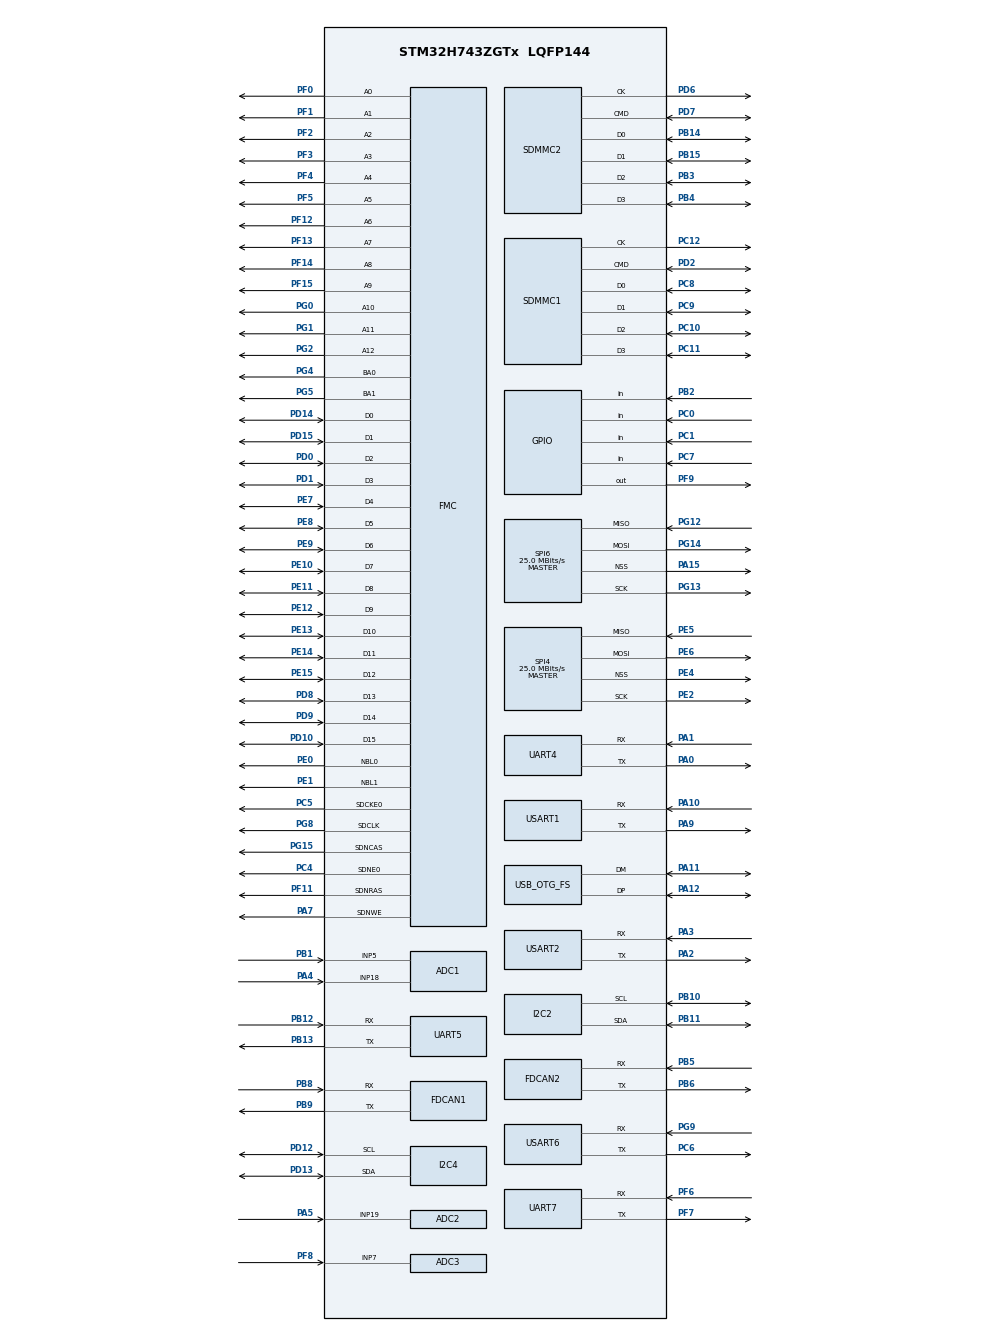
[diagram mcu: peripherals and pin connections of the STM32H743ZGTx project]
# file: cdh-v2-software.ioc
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ADC1.Channel-4\#ChannelRegularConversion=ADC_CHANNEL_18
ADC1.ClockPrescaler=ADC_CLOCK_ASYNC_DIV4
ADC1.NbrOfConversionFlag=1
ADC1.OffsetNumber-4\#ChannelRegularConversion=ADC_OFFSET_NONE
ADC1.OffsetSignedSaturation-4\#ChannelRegularConversion=DISABLE
ADC1.Rank-4\#ChannelRegularConversion=1
ADC1.SamplingTime-4\#ChannelRegularConversion=ADC_SAMPLETIME_1CYCLE_5
ADC1.master=1
ADC2.Channel-0\#ChannelRegularConversion=ADC_CHANNEL_19
ADC2.ClockPrescaler=ADC_CLOCK_ASYNC_DIV4
ADC2.NbrOfConversionFlag=1
ADC2.OffsetNumber-0\#ChannelRegularConversion=ADC_OFFSET_NONE
ADC2.OffsetSignedSaturation-0\#ChannelRegularConversion=DISABLE
ADC2.Rank-0\#ChannelRegularConversion=1
ADC2.SamplingTime-0\#ChannelRegularConversion=ADC_SAMPLETIME_1CYCLE_5
ADC3.Channel-0\#ChannelRegularConversion=ADC_CHANNEL_7
ADC3.ClockPrescaler=ADC_CLOCK_ASYNC_DIV4
ADC3.NbrOfConversionFlag=1
ADC3.OffsetNumber-0\#ChannelRegularConversion=ADC_OFFSET_NONE
ADC3.OffsetSignedSaturation-0\#ChannelRegularConversion=DISABLE
ADC3.Rank-0\#ChannelRegularConversion=1
ADC3.SamplingTime-0\#ChannelRegularConversion=ADC_SAMPLETIME_1CYCLE_5
CORTEX_M7.AccessPermission_S-Cortex_Memory_Protection_Unit_Region1_Settings_S=MPU_REGION_PRIV_RO
CORTEX_M7.AccessPermission_S-Cortex_Memory_Protection_Unit_Region2_Settings_S=MPU_REGION_FULL_ACCESS
CORTEX_M7.BaseAddress_S-Cortex_Memory_Protection_Unit_Region1_Settings_S=0x08000000
CORTEX_M7.BaseAddress_S-Cortex_Memory_Protection_Unit_Region2_Settings_S=0xC0000000
CORTEX_M7.DisableExec_S-Cortex_Memory_Protection_Unit_Region2_Settings_S=MPU_INSTRUCTION_ACCESS_DISABLE
CORTEX_M7.Enable_S-Cortex_Memory_Protection_Unit_Region1_Settings_S=MPU_REGION_ENABLE
CORTEX_M7.Enable_S-Cortex_Memory_Protection_Unit_Region2_Settings_S=MPU_REGION_ENABLE
CORTEX_M7.IsCacheable_S-Cortex_Memory_Protection_Unit_Region1_Settings_S=MPU_ACCESS_CACHEABLE
CORTEX_M7.Number_S-Cortex_Memory_Protection_Unit_Region2_Settings_S=MPU_REGION_NUMBER2
CORTEX_M7.Size_S-Cortex_Memory_Protection_Unit_Region1_Settings_S=MPU_REGION_SIZE_2MB
CORTEX_M7.Size_S-Cortex_Memory_Protection_Unit_Region2_Settings_S=MPU_REGION_SIZE_32MB
CORTEX_M7.SubRegionDisable_S-Cortex_Memory_Protection_Unit_Region1_Settings_S=0x88
CORTEX_M7.TypeExtField_S-Cortex_Memory_Protection_Unit_Region1_Settings_S=MPU_TEX_LEVEL1
CORTEX_M7.TypeExtField_S-Cortex_Memory_Protection_Unit_Region2_Settings_S=MPU_TEX_LEVEL1
CORTEX_M7.default_mode_Activation=1
FATFS.BSP.number=1
FATFS0.BSP.STBoard=false
FATFS0.BSP.api=Unknown
FATFS0.BSP.instance=PC7
FATFS0.BSP.ip=GPIO
FATFS0.BSP.mode=Input
FATFS0.BSP.name=Detect_SDIO
FATFS0.BSP.solution=PC7
FDCAN1.CalculateBaudRateNominal=499999
FDCAN1.CalculateTimeBitNominal=2000
FDCAN1.CalculateTimeQuantumNominal=16.666666666666668
FDCAN1.FrameFormat=FDCAN_FRAME_FD_BRS
FDCAN1.NominalPrescaler=2
FDCAN1.NominalTimeSeg1=95
FDCAN1.NominalTimeSeg2=24
FDCAN2.CalculateBaudRateNominal=499999
FDCAN2.CalculateTimeBitNominal=2000
FDCAN2.CalculateTimeQuantumNominal=16.666666666666668
FDCAN2.FrameFormat=FDCAN_FRAME_FD_BRS
FDCAN2.NominalPrescaler=2
FDCAN2.NominalTimeSeg1=95
FDCAN2.NominalTimeSeg2=24
FMC.CASLatency1=FMC_SDRAM_CAS_LATENCY_2
FMC.ColumnBitsNumber1=FMC_SDRAM_COLUMN_BITS_NUM_9
FMC.ExitSelfRefreshDelay1=10
FMC.LoadToActiveDelay1=2
FMC.RCDDelay1=3
FMC.RPDelay1=3
FMC.ReadBurst1=FMC_SDRAM_RBURST_ENABLE
FMC.ReadPipeDelay1=FMC_SDRAM_RPIPE_DELAY_2
FMC.ReadPipeDelay2=FMC_SDRAM_RPIPE_DELAY_2
FMC.RowCycleDelay1=9
FMC.RowCycleDelay2=9
FMC.SDClockPeriod1=FMC_SDRAM_CLOCK_PERIOD_3
FMC.SDClockPeriod2=FMC_SDRAM_CLOCK_PERIOD_3
FMC.SelfRefreshTime1=6
FMC.WriteRecoveryTime1=3
FREERTOS.HEAP_NUMBER=4
FREERTOS.Tasks01=defaultTask,24,128,StartDefaultTask,Default,NULL,Dynamic,NULL,NULL
FREERTOS.configTOTAL_HEAP_SIZE=262144
FREERTOS.configUSE_NEWLIB_REENTRANT=0
I2C2.Timing=0x00909BEB
I2C4.CustomTiming=Disabled
I2C4.Timing=0x00909BEB
Mcu.Family=STM32H7
Mcu.Name=STM32H743ZGTx
Mcu.Package=LQFP144
NVIC.OTG_FS_IRQn=true\:5\:0\:false\:false\:true\:true\:false\:true\:true
NVIC.PriorityGroup=NVIC_PRIORITYGROUP_4
NVIC.TIM1_UP_IRQn=true\:15\:0\:false\:false\:true\:false\:false\:true\:true
NVIC.TimeBase=TIM1_UP_IRQn
NVIC.TimeBaseIP=TIM1
PA0.Mode=Asynchronous
PA0.Signal=UART4_TX
PA1.Mode=Asynchronous
PA1.Signal=UART4_RX
PA10.Mode=Asynchronous
PA10.Signal=USART1_RX
PA11.Mode=Device_Only
PA11.Signal=USB_OTG_FS_DM
PA12.Mode=Device_Only
PA12.Signal=USB_OTG_FS_DP
PA13\ (JTMS/SWDIO).Mode=Serial_Wire
PA13\ (JTMS/SWDIO).Signal=DEBUG_JTMS-SWDIO
PA14\ (JTCK/SWCLK).Mode=Serial_Wire
PA14\ (JTCK/SWCLK).Signal=DEBUG_JTCK-SWCLK
PA15\ (JTDI).Mode=NSS_Signal_Hard_Output
PA15\ (JTDI).Signal=SPI6_NSS
PA2.Mode=Asynchronous
PA2.Signal=USART2_TX
PA3.Mode=Asynchronous
PA3.Signal=USART2_RX
PA4.Signal=ADCx_INP18
PA5.Signal=ADCx_INP19
PA7.Signal=FMC_SDNWE
PA9.Mode=Asynchronous
PA9.Signal=USART1_TX
PB1.Signal=ADCx_INP5
PB10.Mode=I2C
PB10.Signal=I2C2_SCL
PB11.Mode=I2C
PB11.Signal=I2C2_SDA
PB12.Mode=Asynchronous
PB12.Signal=UART5_RX
PB13.Mode=Asynchronous
PB13.Signal=UART5_TX
PB14.Mode=SD_4_bits_Wide_bus
PB14.Signal=SDMMC2_D0
PB15.Mode=SD_4_bits_Wide_bus
PB15.Signal=SDMMC2_D1
PB2.GPIO_PuPd=GPIO_PULLUP
PB2.Signal=GPIO_Input
PB3\ (JTDO/TRACESWO).Mode=SD_4_bits_Wide_bus
PB3\ (JTDO/TRACESWO).Signal=SDMMC2_D2
PB4\ (NJTRST).Mode=SD_4_bits_Wide_bus
PB4\ (NJTRST).Signal=SDMMC2_D3
PB5.Mode=FDCAN_Activate
PB5.Signal=FDCAN2_RX
PB6.Mode=FDCAN_Activate
PB6.Signal=FDCAN2_TX
PB8.Mode=FDCAN_Activate
PB8.Signal=FDCAN1_RX
PB9.Mode=FDCAN_Activate
PB9.Signal=FDCAN1_TX
PC0.Signal=GPIO_Input
PC1.Signal=GPIO_Input
PC10.Mode=SD_4_bits_Wide_bus
PC10.Signal=SDMMC1_D2
PC11.Mode=SD_4_bits_Wide_bus
PC11.Signal=SDMMC1_D3
PC12.Mode=SD_4_bits_Wide_bus
PC12.Signal=SDMMC1_CK
PC14-OSC32_IN\ (OSC32_IN).Mode=LSE-External-Oscillator
PC14-OSC32_IN\ (OSC32_IN).Signal=RCC_OSC32_IN
PC15-OSC32_OUT\ (OSC32_OUT).Mode=LSE-External-Oscillator
PC15-OSC32_OUT\ (OSC32_OUT).Signal=RCC_OSC32_OUT
PC4.Mode=SdramChipSelect1_1
PC4.Signal=FMC_SDNE0
PC5.Mode=SdramChipSelect1_1
PC5.Signal=FMC_SDCKE0
PC6.Mode=Asynchronous
PC6.Signal=USART6_TX
PC7.GPIO_PuPd=GPIO_PULLUP
PC7.Signal=GPIO_Input
PC8.Mode=SD_4_bits_Wide_bus
PC8.Signal=SDMMC1_D0
PC9.Mode=SD_4_bits_Wide_bus
PC9.Signal=SDMMC1_D1
PD0.Signal=FMC_D2_DA2
PD1.Signal=FMC_D3_DA3
PD10.Signal=FMC_D15_DA15
PD12.Mode=I2C
PD12.Signal=I2C4_SCL
PD13.Mode=I2C
PD13.Signal=I2C4_SDA
PD14.Signal=FMC_D0_DA0
PD15.Signal=FMC_D1_DA1
PD2.Mode=SD_4_bits_Wide_bus
PD2.Signal=SDMMC1_CMD
PD6.Mode=SD_4_bits_Wide_bus
PD6.Signal=SDMMC2_CK
PD7.Mode=SD_4_bits_Wide_bus
PD7.Signal=SDMMC2_CMD
PD8.Signal=FMC_D13_DA13
PD9.Signal=FMC_D14_DA14
PE0.Signal=FMC_NBL0
PE1.Signal=FMC_NBL1
PE10.Signal=FMC_D7_DA7
PE11.Signal=FMC_D8_DA8
PE12.Signal=FMC_D9_DA9
PE13.Signal=FMC_D10_DA10
PE14.Signal=FMC_D11_DA11
PE15.Signal=FMC_D12_DA12
PE2.Mode=Full_Duplex_Master
PE2.Signal=SPI4_SCK
PE4.Mode=NSS_Signal_Hard_Output
PE4.Signal=SPI4_NSS
PE5.Mode=Full_Duplex_Master
PE5.Signal=SPI4_MISO
PE6.Mode=Full_Duplex_Master
PE6.Signal=SPI4_MOSI
PE7.Signal=FMC_D4_DA4
PE8.Signal=FMC_D5_DA5
PE9.Signal=FMC_D6_DA6
PF0.Signal=FMC_A0
PF1.Signal=FMC_A1
PF11.Signal=FMC_SDNRAS
PF12.Signal=FMC_A6
PF13.Signal=FMC_A7
PF14.Signal=FMC_A8
PF15.Signal=FMC_A9
PF2.Signal=FMC_A2
PF3.Signal=FMC_A3
PF4.Signal=FMC_A4
PF5.Signal=FMC_A5
PF6.Mode=Asynchronous
PF6.Signal=UART7_RX
PF7.Mode=Asynchronous
PF7.Signal=UART7_TX
PF8.Mode=IN7-Single-Ended
PF8.Signal=ADC3_INP7
PF9.Signal=GPIO_Output
PG0.Signal=FMC_A10
PG1.Signal=FMC_A11
PG12.Mode=Full_Duplex_Master
PG12.Signal=SPI6_MISO
PG13.Mode=Full_Duplex_Master
PG13.Signal=SPI6_SCK
PG14.Mode=Full_Duplex_Master
PG14.Signal=SPI6_MOSI
PG15.Signal=FMC_SDNCAS
PG2.Signal=FMC_A12
PG4.Signal=FMC_A14_BA0
PG5.Signal=FMC_A15_BA1
PG8.Signal=FMC_SDCLK
PG9.Mode=Asynchronous
PG9.Signal=USART6_RX
PH0-OSC_IN\ (PH0).Mode=HSE-External-Oscillator
PH0-OSC_IN\ (PH0).Signal=RCC_OSC_IN
PH1-OSC_OUT\ (PH1).Mode=HSE-External-Oscillator
PH1-OSC_OUT\ (PH1).Signal=RCC_OSC_OUT
ProjectManager.HeapSize=0x200
ProjectManager.StackSize=0x400
ProjectManager.TargetToolchain=CMake
RAMECC.Instance-RAMECC1_Monitor1=RAMECC1_Monitor1
RAMECC.Instance-RAMECC1_Monitor2=RAMECC1_Monitor2
RAMECC.Instance-RAMECC1_Monitor3=RAMECC1_Monitor3
RAMECC.Instance-RAMECC1_Monitor4=RAMECC1_Monitor4
RAMECC.Instance-RAMECC1_Monitor5=RAMECC1_Monitor5
RAMECC.Instance-RAMECC2_Monitor1=RAMECC2_Monitor1
RAMECC.Instance-RAMECC2_Monitor2=RAMECC2_Monitor2
RAMECC.Instance-RAMECC2_Monitor3=RAMECC2_Monitor3
RAMECC.Instance-RAMECC2_Monitor4=RAMECC2_Monitor4
RAMECC.Instance-RAMECC2_Monitor5=RAMECC2_Monitor5
RAMECC.Instance-RAMECC3_Monitor1=RAMECC3_Monitor1
RAMECC.Instance-RAMECC3_Monitor2=RAMECC3_Monitor2
RCC.ADCFreq_Value=75000000
RCC.APB1Freq_Value=120000000
RCC.APB2Freq_Value=120000000
RCC.APB3Freq_Value=120000000
RCC.APB4Freq_Value=120000000
RCC.CortexFreq_Value=240000000
RCC.D1PPRE=RCC_APB3_DIV2
RCC.D2PPRE1=RCC_APB1_DIV2
RCC.D2PPRE2=RCC_APB2_DIV2
RCC.D3PPRE=RCC_APB4_DIV2
RCC.DIVM1=1
RCC.DIVM2=1
RCC.DIVM3=1
RCC.DIVN1=60
RCC.DIVN2=18
RCC.DIVN3=30
RCC.DIVQ1=4
RCC.DIVQ2=3
RCC.DIVQ3=5
RCC.DIVR2=3
RCC.DIVR3=6
RCC.EnbaleCSS=false
RCC.HCLKFreq_Value=240000000
RCC.HSE_VALUE=8000000
RCC.I2C123CLockSelection=RCC_I2C123CLKSOURCE_PLL3
RCC.I2C4CLockSelection=RCC_I2C4CLKSOURCE_PLL3
RCC.PLL2FRACN=6144
RCC.PLL3FRACN=0
RCC.PLLFRACN=0
RCC.PLLSourceVirtual=RCC_PLLSOURCE_HSE
RCC.SDMMC1CLockSelection=RCC_SDMMCCLKSOURCE_PLL2
RCC.SPI6CLockSelection=RCC_SPI6CLKSOURCE_PLL2
RCC.SYSCLKFreq_VALUE=240000000
RCC.SYSCLKSource=RCC_SYSCLKSOURCE_PLLCLK
RCC.Spi45ClockSelection=RCC_SPI45CLKSOURCE_PLL2
RCC.USART16CLockSelection=RCC_USART16CLKSOURCE_PLL2
RCC.USART234578CLockSelection=RCC_USART234578CLKSOURCE_PLL2
RCC.USBCLockSelection=RCC_USBCLKSOURCE_PLL3
RCC.USBFreq_Value=48000000
SH.ADCx_INP18.0=ADC2_INP18
SH.ADCx_INP18.1=ADC1_INP18,IN18-Single-Ended
SH.ADCx_INP19.0=ADC2_INP19,IN19-Single-Ended
SH.ADCx_INP5.0=ADC1_INP5,IN5-Single-Ended
SH.FMC_A0.0=FMC_A0,13b-sda1
SH.FMC_A1.0=FMC_A1,13b-sda1
SH.FMC_A10.0=FMC_A10,13b-sda1
SH.FMC_A11.0=FMC_A11,13b-sda1
SH.FMC_A12.0=FMC_A12,13b-sda1
SH.FMC_A14_BA0.0=FMC_BA0,FourSdramBanks1
SH.FMC_A15_BA1.0=FMC_BA1,FourSdramBanks1
SH.FMC_A2.0=FMC_A2,13b-sda1
SH.FMC_A3.0=FMC_A3,13b-sda1
SH.FMC_A4.0=FMC_A4,13b-sda1
SH.FMC_A5.0=FMC_A5,13b-sda1
SH.FMC_A6.0=FMC_A6,13b-sda1
SH.FMC_A7.0=FMC_A7,13b-sda1
SH.FMC_A8.0=FMC_A8,13b-sda1
SH.FMC_A9.0=FMC_A9,13b-sda1
SH.FMC_D0_DA0.0=FMC_D0,sd-16b-d1
SH.FMC_D10_DA10.0=FMC_D10,sd-16b-d1
SH.FMC_D11_DA11.0=FMC_D11,sd-16b-d1
SH.FMC_D12_DA12.0=FMC_D12,sd-16b-d1
SH.FMC_D13_DA13.0=FMC_D13,sd-16b-d1
SH.FMC_D14_DA14.0=FMC_D14,sd-16b-d1
SH.FMC_D15_DA15.0=FMC_D15,sd-16b-d1
SH.FMC_D1_DA1.0=FMC_D1,sd-16b-d1
SH.FMC_D2_DA2.0=FMC_D2,sd-16b-d1
SH.FMC_D3_DA3.0=FMC_D3,sd-16b-d1
SH.FMC_D4_DA4.0=FMC_D4,sd-16b-d1
SH.FMC_D5_DA5.0=FMC_D5,sd-16b-d1
SH.FMC_D6_DA6.0=FMC_D6,sd-16b-d1
SH.FMC_D7_DA7.0=FMC_D7,sd-16b-d1
SH.FMC_D8_DA8.0=FMC_D8,sd-16b-d1
SH.FMC_D9_DA9.0=FMC_D9,sd-16b-d1
SH.FMC_NBL0.0=FMC_NBL0,Sd2ByteEnable1
SH.FMC_NBL1.0=FMC_NBL1,Sd2ByteEnable1
SH.FMC_SDCLK.0=FMC_SDCLK,13b-sda1
SH.FMC_SDNCAS.0=FMC_SDNCAS,13b-sda1
SH.FMC_SDNRAS.0=FMC_SDNRAS,13b-sda1
SH.FMC_SDNWE.0=FMC_SDNWE,13b-sda1
SPI4.CalculateBaudRate=25.0 MBits/s
SPI4.Direction=SPI_DIRECTION_2LINES
SPI4.Mode=SPI_MODE_MASTER
SPI4.VirtualNSS=VM_NSSHARD
SPI4.VirtualType=VM_MASTER
SPI6.CalculateBaudRate=25.0 MBits/s
SPI6.Direction=SPI_DIRECTION_2LINES
SPI6.Mode=SPI_MODE_MASTER
SPI6.VirtualNSS=VM_NSSHARD
SPI6.VirtualType=VM_MASTER
USART1.VirtualMode-Asynchronous=VM_ASYNC
USART2.VirtualMode-Asynchronous=VM_ASYNC
USART6.VirtualMode-Asynchronous=VM_ASYNC
USB_DEVICE.CLASS_NAME_FS=CDC
USB_DEVICE.VirtualMode-CDC_FS=Cdc
USB_DEVICE.VirtualModeFS=Cdc_FS
USB_OTG_FS.VirtualMode=Device_Only
VP_CRC_VS_CRC.Mode=CRC_Activate
VP_FATFS_VS_SDIO.Mode=SDIO
VP_FREERTOS_VS_CMSIS_V2.Mode=CMSIS_V2
VP_IWDG1_VS_IWDG.Mode=IWDG_Activate
VP_MEMORYMAP_VS_MEMORYMAP.Mode=CurAppReg
VP_RAMECC_VS_D1_1.Mode=RAMECC1_Monitor1
VP_RAMECC_VS_D1_2.Mode=RAMECC1_Monitor2
VP_RAMECC_VS_D1_3.Mode=RAMECC1_Monitor3
VP_RAMECC_VS_D1_4.Mode=RAMECC1_Monitor4
VP_RAMECC_VS_D1_5.Mode=RAMECC1_Monitor5
VP_RAMECC_VS_D2_1.Mode=RAMECC2_Monitor1
VP_RAMECC_VS_D2_2.Mode=RAMECC2_Monitor2
VP_RAMECC_VS_D2_3.Mode=RAMECC2_Monitor3
VP_RAMECC_VS_D2_4.Mode=RAMECC2_Monitor4
VP_RAMECC_VS_D2_5.Mode=RAMECC2_Monitor5
VP_RAMECC_VS_D3_1.Mode=RAMECC3_Monitor1
VP_RAMECC_VS_D3_2.Mode=RAMECC3_Monitor2
VP_SYS_VS_tim1.Mode=TIM1
VP_TIM6_VS_ClockSourceINT.Mode=Enable_Timer
VP_TIM7_VS_ClockSourceINT.Mode=Enable_Timer
VP_USB_DEVICE_VS_USB_DEVICE_CDC_FS.Mode=CDC_FS
board=custom

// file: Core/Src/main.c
/* USER CODE BEGIN Header */
/**
  ******************************************************************************
  * @file           : main.c
  * @brief          : Main program body
  ******************************************************************************
  * @attention
  *
  * Copyright (c) 2026 STMicroelectronics.
  * All rights reserved.
  *
  * This software is licensed under terms that can be found in the LICENSE file
  * in the root directory of this software component.
  * If no LICENSE file comes with this software, it is provided AS-IS.
  *
  ******************************************************************************
  */
/* USER CODE END Header */
#include "main.h"
#include "FreeRTOS.h"
#include "cmsis_os2.h"
#include "fatfs.h"
#include "usb_device.h"

/* USER CODE BEGIN Includes */
#include "cdh_main.h"

/* USER CODE END Includes */

ADC_HandleTypeDef hadc1;
ADC_HandleTypeDef hadc2;
ADC_HandleTypeDef hadc3;

CRC_HandleTypeDef hcrc;

FDCAN_HandleTypeDef hfdcan1;
FDCAN_HandleTypeDef hfdcan2;

I2C_HandleTypeDef hi2c2;
I2C_HandleTypeDef hi2c4;

IWDG_HandleTypeDef hiwdg1;

RAMECC_HandleTypeDef hramecc1_m1;
RAMECC_HandleTypeDef hramecc1_m2;
RAMECC_HandleTypeDef hramecc1_m3;
RAMECC_HandleTypeDef hramecc1_m4;
RAMECC_HandleTypeDef hramecc1_m5;
RAMECC_HandleTypeDef hramecc2_m1;
RAMECC_HandleTypeDef hramecc2_m2;
RAMECC_HandleTypeDef hramecc2_m3;
RAMECC_HandleTypeDef hramecc2_m4;
RAMECC_HandleTypeDef hramecc2_m5;
RAMECC_HandleTypeDef hramecc3_m1;
RAMECC_HandleTypeDef hramecc3_m2;

SD_HandleTypeDef hsd1;
SD_HandleTypeDef hsd2;

SPI_HandleTypeDef hspi4;
SPI_HandleTypeDef hspi6;

TIM_HandleTypeDef htim6;
TIM_HandleTypeDef htim7;

UART_HandleTypeDef huart4;
UART_HandleTypeDef huart5;
UART_HandleTypeDef huart7;
UART_HandleTypeDef huart1;
UART_HandleTypeDef huart2;
UART_HandleTypeDef huart6;

SDRAM_HandleTypeDef hsdram1;

/* Definitions for defaultTask */
osThreadId_t defaultTaskHandle;
const osThreadAttr_t defaultTask_attributes = {
  .name = "defaultTask",
  .stack_size = 128 * 4,
  .priority = (osPriority_t) osPriorityNormal,
};

void SystemClock_Config(void);
void PeriphCommonClock_Config(void);
static void MPU_Config(void);
static void MX_GPIO_Init(void);
static void MX_ADC1_Init(void);
static void MX_ADC2_Init(void);
static void MX_ADC3_Init(void);
static void MX_FDCAN1_Init(void);
static void MX_FDCAN2_Init(void);
static void MX_FMC_Init(void);
static void MX_I2C2_Init(void);
static void MX_I2C4_Init(void);
static void MX_SDMMC1_SD_Init(void);
static void MX_SDMMC2_SD_Init(void);
static void MX_SPI4_Init(void);
static void MX_SPI6_Init(void);
static void MX_UART4_Init(void);
static void MX_UART5_Init(void);
static void MX_UART7_Init(void);
static void MX_USART1_UART_Init(void);
static void MX_USART2_UART_Init(void);
static void MX_USART6_UART_Init(void);
static void MX_CRC_Init(void);
static void MX_IWDG1_Init(void);
static void MX_RAMECC_Init(void);
static void MX_TIM6_Init(void);
static void MX_TIM7_Init(void);
void StartDefaultTask(void *argument);

int main(void)
{

  /* MPU Configuration--------------------------------------------------------*/
  MPU_Config();

  /* MCU Configuration--------------------------------------------------------*/

  /* Configure The Vector Table address */
  SCB->VTOR = 0x08000000;

  /* Reset of all peripherals, Initializes the Flash interface and the Systick. */
  HAL_Init();

  /* Configure the system clock */
  SystemClock_Config();

  /* Configure the peripherals common clocks */
  PeriphCommonClock_Config();

  /* Initialize all configured peripherals */
  MX_GPIO_Init();
  MX_ADC1_Init();
  MX_ADC2_Init();
  MX_ADC3_Init();
  MX_FDCAN1_Init();
  MX_FDCAN2_Init();
  MX_FMC_Init();
  MX_I2C2_Init();
  MX_I2C4_Init();
  MX_SDMMC1_SD_Init();
  MX_SDMMC2_SD_Init();
  MX_SPI4_Init();
  MX_SPI6_Init();
  MX_UART4_Init();
  MX_UART5_Init();
  MX_UART7_Init();
  MX_USART1_UART_Init();
  MX_USART2_UART_Init();
  MX_USART6_UART_Init();
  MX_CRC_Init();
  MX_IWDG1_Init();
  MX_RAMECC_Init();
  MX_TIM6_Init();
  MX_TIM7_Init();
  MX_FATFS_Init();

  /* Init scheduler */
  osKernelInitialize();

  /* Create the thread(s) */
  /* creation of defaultTask */
  defaultTaskHandle = osThreadNew(StartDefaultTask, NULL, &defaultTask_attributes);

  /* Start scheduler */
  osKernelStart();

  /* We should never get here as control is now taken by the scheduler */

  /* Infinite loop */
  while (1)
  {

  }
}

void SystemClock_Config(void)
{
  RCC_OscInitTypeDef RCC_OscInitStruct = {0};
  RCC_ClkInitTypeDef RCC_ClkInitStruct = {0};

  /** Supply configuration update enable
  */
  HAL_PWREx_ConfigSupply(PWR_LDO_SUPPLY);

  /** Configure the main internal regulator output voltage
  */
  __HAL_PWR_VOLTAGESCALING_CONFIG(PWR_REGULATOR_VOLTAGE_SCALE0);

  while(!__HAL_PWR_GET_FLAG(PWR_FLAG_VOSRDY)) {}

  /** Initializes the RCC Oscillators according to the specified parameters
  * in the RCC_OscInitTypeDef structure.
  */
  RCC_OscInitStruct.OscillatorType = RCC_OSCILLATORTYPE_LSI|RCC_OSCILLATORTYPE_HSE;
  RCC_OscInitStruct.HSEState = RCC_HSE_ON;
  RCC_OscInitStruct.LSIState = RCC_LSI_ON;
  RCC_OscInitStruct.PLL.PLLState = RCC_PLL_ON;
  RCC_OscInitStruct.PLL.PLLSource = RCC_PLLSOURCE_HSE;
  RCC_OscInitStruct.PLL.PLLM = 1;
  RCC_OscInitStruct.PLL.PLLN = 60;
  RCC_OscInitStruct.PLL.PLLP = 2;
  RCC_OscInitStruct.PLL.PLLQ = 4;
  RCC_OscInitStruct.PLL.PLLR = 2;
  RCC_OscInitStruct.PLL.PLLRGE = RCC_PLL1VCIRANGE_3;
  RCC_OscInitStruct.PLL.PLLVCOSEL = RCC_PLL1VCOWIDE;
  RCC_OscInitStruct.PLL.PLLFRACN = 0;
  if (HAL_RCC_OscConfig(&RCC_OscInitStruct) != HAL_OK)
  {
    Error_Handler();
  }

  /** Initializes the CPU, AHB and APB buses clocks
  */
  RCC_ClkInitStruct.ClockType = RCC_CLOCKTYPE_HCLK|RCC_CLOCKTYPE_SYSCLK
                              |RCC_CLOCKTYPE_PCLK1|RCC_CLOCKTYPE_PCLK2
                              |RCC_CLOCKTYPE_D3PCLK1|RCC_CLOCKTYPE_D1PCLK1;
  RCC_ClkInitStruct.SYSCLKSource = RCC_SYSCLKSOURCE_PLLCLK;
  RCC_ClkInitStruct.SYSCLKDivider = RCC_SYSCLK_DIV1;
  RCC_ClkInitStruct.AHBCLKDivider = RCC_HCLK_DIV1;
  RCC_ClkInitStruct.APB3CLKDivider = RCC_APB3_DIV2;
  RCC_ClkInitStruct.APB1CLKDivider = RCC_APB1_DIV2;
  RCC_ClkInitStruct.APB2CLKDivider = RCC_APB2_DIV2;
  RCC_ClkInitStruct.APB4CLKDivider = RCC_APB4_DIV2;

  if (HAL_RCC_ClockConfig(&RCC_ClkInitStruct, FLASH_LATENCY_4) != HAL_OK)
  {
    Error_Handler();
  }
}

void PeriphCommonClock_Config(void)
{
  RCC_PeriphCLKInitTypeDef PeriphClkInitStruct = {0};

  /** Initializes the peripherals clock
  */
  PeriphClkInitStruct.PeriphClockSelection = RCC_PERIPHCLK_USB|RCC_PERIPHCLK_I2C4
                              |RCC_PERIPHCLK_SPI6|RCC_PERIPHCLK_ADC
                              |RCC_PERIPHCLK_I2C2|RCC_PERIPHCLK_SDMMC
                              |RCC_PERIPHCLK_SPI4|RCC_PERIPHCLK_UART5
                              |RCC_PERIPHCLK_USART1|RCC_PERIPHCLK_USART6
                              |RCC_PERIPHCLK_UART7|RCC_PERIPHCLK_UART4
                              |RCC_PERIPHCLK_USART2;
  PeriphClkInitStruct.PLL2.PLL2M = 1;
  PeriphClkInitStruct.PLL2.PLL2N = 18;
  PeriphClkInitStruct.PLL2.PLL2P = 2;
  PeriphClkInitStruct.PLL2.PLL2Q = 3;
  PeriphClkInitStruct.PLL2.PLL2R = 3;
  PeriphClkInitStruct.PLL2.PLL2RGE = RCC_PLL2VCIRANGE_3;
  PeriphClkInitStruct.PLL2.PLL2VCOSEL = RCC_PLL2VCOMEDIUM;
  PeriphClkInitStruct.PLL2.PLL2FRACN = 6144;
  PeriphClkInitStruct.PLL3.PLL3M = 1;
  PeriphClkInitStruct.PLL3.PLL3N = 30;
  PeriphClkInitStruct.PLL3.PLL3P = 2;
  PeriphClkInitStruct.PLL3.PLL3Q = 5;
  PeriphClkInitStruct.PLL3.PLL3R = 6;
  PeriphClkInitStruct.PLL3.PLL3RGE = RCC_PLL3VCIRANGE_3;
  PeriphClkInitStruct.PLL3.PLL3VCOSEL = RCC_PLL3VCOWIDE;
  PeriphClkInitStruct.PLL3.PLL3FRACN = 0;
  PeriphClkInitStruct.SdmmcClockSelection = RCC_SDMMCCLKSOURCE_PLL2;
  PeriphClkInitStruct.Spi45ClockSelection = RCC_SPI45CLKSOURCE_PLL2;
  PeriphClkInitStruct.Usart234578ClockSelection = RCC_USART234578CLKSOURCE_PLL2;
  PeriphClkInitStruct.Usart16ClockSelection = RCC_USART16CLKSOURCE_PLL2;
  PeriphClkInitStruct.I2c123ClockSelection = RCC_I2C123CLKSOURCE_PLL3;
  PeriphClkInitStruct.UsbClockSelection = RCC_USBCLKSOURCE_PLL3;
  PeriphClkInitStruct.I2c4ClockSelection = RCC_I2C4CLKSOURCE_PLL3;
  PeriphClkInitStruct.AdcClockSelection = RCC_ADCCLKSOURCE_PLL2;
  PeriphClkInitStruct.Spi6ClockSelection = RCC_SPI6CLKSOURCE_PLL2;
  if (HAL_RCCEx_PeriphCLKConfig(&PeriphClkInitStruct) != HAL_OK)
  {
    Error_Handler();
  }
}

static void MX_ADC1_Init(void)
{

  ADC_MultiModeTypeDef multimode = {0};
  ADC_ChannelConfTypeDef sConfig = {0};

  /** Common config
  */
  hadc1.Instance = ADC1;
  hadc1.Init.ClockPrescaler = ADC_CLOCK_ASYNC_DIV4;
  hadc1.Init.Resolution = ADC_RESOLUTION_16B;
  hadc1.Init.ScanConvMode = ADC_SCAN_DISABLE;
  hadc1.Init.EOCSelection = ADC_EOC_SINGLE_CONV;
  hadc1.Init.LowPowerAutoWait = DISABLE;
  hadc1.Init.ContinuousConvMode = DISABLE;
  hadc1.Init.NbrOfConversion = 1;
  hadc1.Init.DiscontinuousConvMode = DISABLE;
  hadc1.Init.ExternalTrigConv = ADC_SOFTWARE_START;
  hadc1.Init.ExternalTrigConvEdge = ADC_EXTERNALTRIGCONVEDGE_NONE;
  hadc1.Init.ConversionDataManagement = ADC_CONVERSIONDATA_DR;
  hadc1.Init.Overrun = ADC_OVR_DATA_PRESERVED;
  hadc1.Init.LeftBitShift = ADC_LEFTBITSHIFT_NONE;
  hadc1.Init.OversamplingMode = DISABLE;
  hadc1.Init.Oversampling.Ratio = 1;
  if (HAL_ADC_Init(&hadc1) != HAL_OK)
  {
    Error_Handler();
  }

  /** Configure the ADC multi-mode
  */
  multimode.Mode = ADC_MODE_INDEPENDENT;
  if (HAL_ADCEx_MultiModeConfigChannel(&hadc1, &multimode) != HAL_OK)
  {
    Error_Handler();
  }

  /** Configure Regular Channel
  */
  sConfig.Channel = ADC_CHANNEL_18;
  sConfig.Rank = ADC_REGULAR_RANK_1;
  sConfig.SamplingTime = ADC_SAMPLETIME_1CYCLE_5;
  sConfig.SingleDiff = ADC_SINGLE_ENDED;
  sConfig.OffsetNumber = ADC_OFFSET_NONE;
  sConfig.Offset = 0;
  sConfig.OffsetSignedSaturation = DISABLE;
  if (HAL_ADC_ConfigChannel(&hadc1, &sConfig) != HAL_OK)
  {
    Error_Handler();
  }

}

static void MX_ADC2_Init(void)
{

  ADC_ChannelConfTypeDef sConfig = {0};

  /** Common config
  */
  hadc2.Instance = ADC2;
  hadc2.Init.ClockPrescaler = ADC_CLOCK_ASYNC_DIV4;
  hadc2.Init.Resolution = ADC_RESOLUTION_16B;
  hadc2.Init.ScanConvMode = ADC_SCAN_DISABLE;
  hadc2.Init.EOCSelection = ADC_EOC_SINGLE_CONV;
  hadc2.Init.LowPowerAutoWait = DISABLE;
  hadc2.Init.ContinuousConvMode = DISABLE;
  hadc2.Init.NbrOfConversion = 1;
  hadc2.Init.DiscontinuousConvMode = DISABLE;
  hadc2.Init.ExternalTrigConv = ADC_SOFTWARE_START;
  hadc2.Init.ExternalTrigConvEdge = ADC_EXTERNALTRIGCONVEDGE_NONE;
  hadc2.Init.ConversionDataManagement = ADC_CONVERSIONDATA_DR;
  hadc2.Init.Overrun = ADC_OVR_DATA_PRESERVED;
  hadc2.Init.LeftBitShift = ADC_LEFTBITSHIFT_NONE;
  hadc2.Init.OversamplingMode = DISABLE;
  hadc2.Init.Oversampling.Ratio = 1;
  if (HAL_ADC_Init(&hadc2) != HAL_OK)
  {
    Error_Handler();
  }

  /** Configure Regular Channel
  */
  sConfig.Channel = ADC_CHANNEL_19;
  sConfig.Rank = ADC_REGULAR_RANK_1;
  sConfig.SamplingTime = ADC_SAMPLETIME_1CYCLE_5;
  sConfig.SingleDiff = ADC_SINGLE_ENDED;
  sConfig.OffsetNumber = ADC_OFFSET_NONE;
  sConfig.Offset = 0;
  sConfig.OffsetSignedSaturation = DISABLE;
  if (HAL_ADC_ConfigChannel(&hadc2, &sConfig) != HAL_OK)
  {
    Error_Handler();
  }

}

static void MX_ADC3_Init(void)
{

  ADC_ChannelConfTypeDef sConfig = {0};

  /** Common config
  */
  hadc3.Instance = ADC3;
  hadc3.Init.ClockPrescaler = ADC_CLOCK_ASYNC_DIV1;
  hadc3.Init.ScanConvMode = ADC_SCAN_DISABLE;
  hadc3.Init.EOCSelection = ADC_EOC_SINGLE_CONV;
  hadc3.Init.LowPowerAutoWait = DISABLE;
  hadc3.Init.ContinuousConvMode = DISABLE;
  hadc3.Init.NbrOfConversion = 1;
  hadc3.Init.DiscontinuousConvMode = DISABLE;
  hadc3.Init.ExternalTrigConv = ADC_SOFTWARE_START;
  hadc3.Init.ExternalTrigConvEdge = ADC_EXTERNALTRIGCONVEDGE_NONE;
  hadc3.Init.ConversionDataManagement = ADC_CONVERSIONDATA_DR;
  hadc3.Init.Overrun = ADC_OVR_DATA_PRESERVED;
  hadc3.Init.LeftBitShift = ADC_LEFTBITSHIFT_NONE;
  hadc3.Init.OversamplingMode = DISABLE;
  hadc3.Init.Oversampling.Ratio = 1;
  if (HAL_ADC_Init(&hadc3) != HAL_OK)
  {
    Error_Handler();
  }
  hadc3.Init.ClockPrescaler = ADC_CLOCK_ASYNC_DIV4;
  hadc3.Init.Resolution = ADC_RESOLUTION_16B;
  if (HAL_ADC_Init(&hadc3) != HAL_OK)
  {
    Error_Handler();
  }

  /** Configure Regular Channel
  */
  sConfig.Channel = ADC_CHANNEL_7;
  sConfig.Rank = ADC_REGULAR_RANK_1;
  sConfig.SamplingTime = ADC_SAMPLETIME_1CYCLE_5;
  sConfig.SingleDiff = ADC_SINGLE_ENDED;
  sConfig.OffsetNumber = ADC_OFFSET_NONE;
  sConfig.Offset = 0;
  sConfig.OffsetSignedSaturation = DISABLE;
  if (HAL_ADC_ConfigChannel(&hadc3, &sConfig) != HAL_OK)
  {
    Error_Handler();
  }

}

static void MX_CRC_Init(void)
{

  hcrc.Instance = CRC;
  hcrc.Init.DefaultPolynomialUse = DEFAULT_POLYNOMIAL_ENABLE;
  hcrc.Init.DefaultInitValueUse = DEFAULT_INIT_VALUE_ENABLE;
  hcrc.Init.InputDataInversionMode = CRC_INPUTDATA_INVERSION_NONE;
  hcrc.Init.OutputDataInversionMode = CRC_OUTPUTDATA_INVERSION_DISABLE;
  hcrc.InputDataFormat = CRC_INPUTDATA_FORMAT_BYTES;
  if (HAL_CRC_Init(&hcrc) != HAL_OK)
  {
    Error_Handler();
  }

}

static void MX_FDCAN1_Init(void)
{

  hfdcan1.Instance = FDCAN1;
  hfdcan1.Init.FrameFormat = FDCAN_FRAME_FD_BRS;
  hfdcan1.Init.Mode = FDCAN_MODE_NORMAL;
  hfdcan1.Init.AutoRetransmission = DISABLE;
  hfdcan1.Init.TransmitPause = DISABLE;
  hfdcan1.Init.ProtocolException = DISABLE;
  hfdcan1.Init.NominalPrescaler = 2;
  hfdcan1.Init.NominalSyncJumpWidth = 1;
  hfdcan1.Init.NominalTimeSeg1 = 95;
  hfdcan1.Init.NominalTimeSeg2 = 24;
  hfdcan1.Init.DataPrescaler = 1;
  hfdcan1.Init.DataSyncJumpWidth = 1;
  hfdcan1.Init.DataTimeSeg1 = 1;
  hfdcan1.Init.DataTimeSeg2 = 1;
  hfdcan1.Init.MessageRAMOffset = 0;
  hfdcan1.Init.StdFiltersNbr = 0;
  hfdcan1.Init.ExtFiltersNbr = 0;
  hfdcan1.Init.RxFifo0ElmtsNbr = 0;
  hfdcan1.Init.RxFifo0ElmtSize = FDCAN_DATA_BYTES_8;
  hfdcan1.Init.RxFifo1ElmtsNbr = 0;
  hfdcan1.Init.RxFifo1ElmtSize = FDCAN_DATA_BYTES_8;
  hfdcan1.Init.RxBuffersNbr = 0;
  hfdcan1.Init.RxBufferSize = FDCAN_DATA_BYTES_8;
  hfdcan1.Init.TxEventsNbr = 0;
  hfdcan1.Init.TxBuffersNbr = 0;
  hfdcan1.Init.TxFifoQueueElmtsNbr = 0;
  hfdcan1.Init.TxFifoQueueMode = FDCAN_TX_FIFO_OPERATION;
  hfdcan1.Init.TxElmtSize = FDCAN_DATA_BYTES_8;
  if (HAL_FDCAN_Init(&hfdcan1) != HAL_OK)
  {
    Error_Handler();
  }

}

static void MX_FDCAN2_Init(void)
{

  hfdcan2.Instance = FDCAN2;
  hfdcan2.Init.FrameFormat = FDCAN_FRAME_FD_BRS;
  hfdcan2.Init.Mode = FDCAN_MODE_NORMAL;
  hfdcan2.Init.AutoRetransmission = DISABLE;
  hfdcan2.Init.TransmitPause = DISABLE;
  hfdcan2.Init.ProtocolException = DISABLE;
  hfdcan2.Init.NominalPrescaler = 2;
  hfdcan2.Init.NominalSyncJumpWidth = 1;
  hfdcan2.Init.NominalTimeSeg1 = 95;
  hfdcan2.Init.NominalTimeSeg2 = 24;
  hfdcan2.Init.DataPrescaler = 1;
  hfdcan2.Init.DataSyncJumpWidth = 1;
  hfdcan2.Init.DataTimeSeg1 = 1;
  hfdcan2.Init.DataTimeSeg2 = 1;
  hfdcan2.Init.MessageRAMOffset = 0;
  hfdcan2.Init.StdFiltersNbr = 0;
  hfdcan2.Init.ExtFiltersNbr = 0;
  hfdcan2.Init.RxFifo0ElmtsNbr = 0;
  hfdcan2.Init.RxFifo0ElmtSize = FDCAN_DATA_BYTES_8;
  hfdcan2.Init.RxFifo1ElmtsNbr = 0;
  hfdcan2.Init.RxFifo1ElmtSize = FDCAN_DATA_BYTES_8;
  hfdcan2.Init.RxBuffersNbr = 0;
  hfdcan2.Init.RxBufferSize = FDCAN_DATA_BYTES_8;
  hfdcan2.Init.TxEventsNbr = 0;
  hfdcan2.Init.TxBuffersNbr = 0;
  hfdcan2.Init.TxFifoQueueElmtsNbr = 0;
  hfdcan2.Init.TxFifoQueueMode = FDCAN_TX_FIFO_OPERATION;
  hfdcan2.Init.TxElmtSize = FDCAN_DATA_BYTES_8;
  if (HAL_FDCAN_Init(&hfdcan2) != HAL_OK)
  {
    Error_Handler();
  }

}

static void MX_I2C2_Init(void)
{

  hi2c2.Instance = I2C2;
  hi2c2.Init.Timing = 0x00909BEB;
  hi2c2.Init.OwnAddress1 = 0;
  hi2c2.Init.AddressingMode = I2C_ADDRESSINGMODE_7BIT;
  hi2c2.Init.DualAddressMode = I2C_DUALADDRESS_DISABLE;
  hi2c2.Init.OwnAddress2 = 0;
  hi2c2.Init.OwnAddress2Masks = I2C_OA2_NOMASK;
  hi2c2.Init.GeneralCallMode = I2C_GENERALCALL_DISABLE;
  hi2c2.Init.NoStretchMode = I2C_NOSTRETCH_DISABLE;
  if (HAL_I2C_Init(&hi2c2) != HAL_OK)
  {
    Error_Handler();
  }

  /** Configure Analogue filter
  */
  if (HAL_I2CEx_ConfigAnalogFilter(&hi2c2, I2C_ANALOGFILTER_ENABLE) != HAL_OK)
  {
    Error_Handler();
  }

  /** Configure Digital filter
  */
  if (HAL_I2CEx_ConfigDigitalFilter(&hi2c2, 0) != HAL_OK)
  {
    Error_Handler();
  }

}

static void MX_I2C4_Init(void)
{

  hi2c4.Instance = I2C4;
  hi2c4.Init.Timing = 0x00909BEB;
  hi2c4.Init.OwnAddress1 = 0;
  hi2c4.Init.AddressingMode = I2C_ADDRESSINGMODE_7BIT;
  hi2c4.Init.DualAddressMode = I2C_DUALADDRESS_DISABLE;
  hi2c4.Init.OwnAddress2 = 0;
  hi2c4.Init.OwnAddress2Masks = I2C_OA2_NOMASK;
  hi2c4.Init.GeneralCallMode = I2C_GENERALCALL_DISABLE;
  hi2c4.Init.NoStretchMode = I2C_NOSTRETCH_DISABLE;
  if (HAL_I2C_Init(&hi2c4) != HAL_OK)
  {
    Error_Handler();
  }

  /** Configure Analogue filter
  */
  if (HAL_I2CEx_ConfigAnalogFilter(&hi2c4, I2C_ANALOGFILTER_ENABLE) != HAL_OK)
  {
    Error_Handler();
  }

  /** Configure Digital filter
  */
  if (HAL_I2CEx_ConfigDigitalFilter(&hi2c4, 0) != HAL_OK)
  {
    Error_Handler();
  }

}

static void MX_IWDG1_Init(void)
{

  hiwdg1.Instance = IWDG1;
  hiwdg1.Init.Prescaler = IWDG_PRESCALER_4;
  hiwdg1.Init.Window = 4095;
  hiwdg1.Init.Reload = 4095;
  if (HAL_IWDG_Init(&hiwdg1) != HAL_OK)
  {
    Error_Handler();
  }

}

static void MX_RAMECC_Init(void)
{

  /** Initialize RAMECC1 M1 : AXI SRAM
  */
  hramecc1_m1.Instance = RAMECC1_Monitor1;
  if (HAL_RAMECC_Init(&hramecc1_m1) != HAL_OK)
  {
    Error_Handler();
  }

  /** Initialize RAMECC1 M2 : ITCM-RAM
  */
  hramecc1_m2.Instance = RAMECC1_Monitor2;
  if (HAL_RAMECC_Init(&hramecc1_m2) != HAL_OK)
  {
    Error_Handler();
  }

  /** Initialize RAMECC1 M3 : D0TCM-RAM
  */
  hramecc1_m3.Instance = RAMECC1_Monitor3;
  if (HAL_RAMECC_Init(&hramecc1_m3) != HAL_OK)
  {
    Error_Handler();
  }

  /** Initialize RAMECC1 M4 : D1TCM-RAM
  */
  hramecc1_m4.Instance = RAMECC1_Monitor4;
  if (HAL_RAMECC_Init(&hramecc1_m4) != HAL_OK)
  {
    Error_Handler();
  }

  /** Initialize RAMECC1 M5 : ETM RAM
  */
  hramecc1_m5.Instance = RAMECC1_Monitor5;
  if (HAL_RAMECC_Init(&hramecc1_m5) != HAL_OK)
  {
    Error_Handler();
  }

  /** Initialize RAMECC2 M1 : SRAM1_0
  */
  hramecc2_m1.Instance = RAMECC2_Monitor1;
  if (HAL_RAMECC_Init(&hramecc2_m1) != HAL_OK)
  {
    Error_Handler();
  }

  /** Initialize RAMECC2 M2 SRAM1_1
  */
  hramecc2_m2.Instance = RAMECC2_Monitor2;
  if (HAL_RAMECC_Init(&hramecc2_m2) != HAL_OK)
  {
    Error_Handler();
  }

  /** Initialize RAMECC2 M3 : SRAM2_0
  */
  hramecc2_m3.Instance = RAMECC2_Monitor3;
  if (HAL_RAMECC_Init(&hramecc2_m3) != HAL_OK)
  {
    Error_Handler();
  }

  /** Initialize RAMECC2 M4 : SRAM2_1
  */
  hramecc2_m4.Instance = RAMECC2_Monitor4;
  if (HAL_RAMECC_Init(&hramecc2_m4) != HAL_OK)
  {
    Error_Handler();
  }

  /** Initialize RAMECC2 M5 : SRAM3
  */
  hramecc2_m5.Instance = RAMECC2_Monitor5;
  if (HAL_RAMECC_Init(&hramecc2_m5) != HAL_OK)
  {
    Error_Handler();
  }

  /** Initialize RAMECC3 M1 : SRAM4
  */
  hramecc3_m1.Instance = RAMECC3_Monitor1;
  if (HAL_RAMECC_Init(&hramecc3_m1) != HAL_OK)
  {
    Error_Handler();
  }

  /** Initialize RAMECC3 M2 : Backup RAM
  */
  hramecc3_m2.Instance = RAMECC3_Monitor2;
  if (HAL_RAMECC_Init(&hramecc3_m2) != HAL_OK)
  {
    Error_Handler();
  }

}

static void MX_SDMMC1_SD_Init(void)
{

  hsd1.Instance = SDMMC1;
  hsd1.Init.ClockEdge = SDMMC_CLOCK_EDGE_RISING;
  hsd1.Init.ClockPowerSave = SDMMC_CLOCK_POWER_SAVE_DISABLE;
  hsd1.Init.BusWide = SDMMC_BUS_WIDE_4B;
  hsd1.Init.HardwareFlowControl = SDMMC_HARDWARE_FLOW_CONTROL_DISABLE;
  hsd1.Init.ClockDiv = 0;
  if (HAL_SD_Init(&hsd1) != HAL_OK)
  {
    Error_Handler();
  }

}

static void MX_SDMMC2_SD_Init(void)
{

  hsd2.Instance = SDMMC2;
  hsd2.Init.ClockEdge = SDMMC_CLOCK_EDGE_RISING;
  hsd2.Init.ClockPowerSave = SDMMC_CLOCK_POWER_SAVE_DISABLE;
  hsd2.Init.BusWide = SDMMC_BUS_WIDE_4B;
  hsd2.Init.HardwareFlowControl = SDMMC_HARDWARE_FLOW_CONTROL_DISABLE;
  hsd2.Init.ClockDiv = 0;
  if (HAL_SD_Init(&hsd2) != HAL_OK)
  {
    Error_Handler();
  }

}

static void MX_SPI4_Init(void)
{

  /* SPI4 parameter configuration*/
  hspi4.Instance = SPI4;
  hspi4.Init.Mode = SPI_MODE_MASTER;
  hspi4.Init.Direction = SPI_DIRECTION_2LINES;
  hspi4.Init.DataSize = SPI_DATASIZE_4BIT;
  hspi4.Init.CLKPolarity = SPI_POLARITY_LOW;
  hspi4.Init.CLKPhase = SPI_PHASE_1EDGE;
  hspi4.Init.NSS = SPI_NSS_HARD_OUTPUT;
  hspi4.Init.BaudRatePrescaler = SPI_BAUDRATEPRESCALER_2;
  hspi4.Init.FirstBit = SPI_FIRSTBIT_MSB;
  hspi4.Init.TIMode = SPI_TIMODE_DISABLE;
  hspi4.Init.CRCCalculation = SPI_CRCCALCULATION_DISABLE;
  hspi4.Init.CRCPolynomial = 0x0;
  hspi4.Init.NSSPMode = SPI_NSS_PULSE_ENABLE;
  hspi4.Init.NSSPolarity = SPI_NSS_POLARITY_LOW;
  hspi4.Init.FifoThreshold = SPI_FIFO_THRESHOLD_01DATA;
  hspi4.Init.TxCRCInitializationPattern = SPI_CRC_INITIALIZATION_ALL_ZERO_PATTERN;
  hspi4.Init.RxCRCInitializationPattern = SPI_CRC_INITIALIZATION_ALL_ZERO_PATTERN;
  hspi4.Init.MasterSSIdleness = SPI_MASTER_SS_IDLENESS_00CYCLE;
  hspi4.Init.MasterInterDataIdleness = SPI_MASTER_INTERDATA_IDLENESS_00CYCLE;
  hspi4.Init.MasterReceiverAutoSusp = SPI_MASTER_RX_AUTOSUSP_DISABLE;
  hspi4.Init.MasterKeepIOState = SPI_MASTER_KEEP_IO_STATE_DISABLE;
  hspi4.Init.IOSwap = SPI_IO_SWAP_DISABLE;
  if (HAL_SPI_Init(&hspi4) != HAL_OK)
  {
    Error_Handler();
  }

}

static void MX_SPI6_Init(void)
{

  /* SPI6 parameter configuration*/
  hspi6.Instance = SPI6;
  hspi6.Init.Mode = SPI_MODE_MASTER;
  hspi6.Init.Direction = SPI_DIRECTION_2LINES;
  hspi6.Init.DataSize = SPI_DATASIZE_4BIT;
  hspi6.Init.CLKPolarity = SPI_POLARITY_LOW;
  hspi6.Init.CLKPhase = SPI_PHASE_1EDGE;
  hspi6.Init.NSS = SPI_NSS_HARD_OUTPUT;
  hspi6.Init.BaudRatePrescaler = SPI_BAUDRATEPRESCALER_2;
  hspi6.Init.FirstBit = SPI_FIRSTBIT_MSB;
  hspi6.Init.TIMode = SPI_TIMODE_DISABLE;
  hspi6.Init.CRCCalculation = SPI_CRCCALCULATION_DISABLE;
  hspi6.Init.CRCPolynomial = 0x0;
  hspi6.Init.NSSPMode = SPI_NSS_PULSE_ENABLE;
  hspi6.Init.NSSPolarity = SPI_NSS_POLARITY_LOW;
  hspi6.Init.FifoThreshold = SPI_FIFO_THRESHOLD_01DATA;
  hspi6.Init.TxCRCInitializationPattern = SPI_CRC_INITIALIZATION_ALL_ZERO_PATTERN;
  hspi6.Init.RxCRCInitializationPattern = SPI_CRC_INITIALIZATION_ALL_ZERO_PATTERN;
  hspi6.Init.MasterSSIdleness = SPI_MASTER_SS_IDLENESS_00CYCLE;
  hspi6.Init.MasterInterDataIdleness = SPI_MASTER_INTERDATA_IDLENESS_00CYCLE;
  hspi6.Init.MasterReceiverAutoSusp = SPI_MASTER_RX_AUTOSUSP_DISABLE;
  hspi6.Init.MasterKeepIOState = SPI_MASTER_KEEP_IO_STATE_DISABLE;
  hspi6.Init.IOSwap = SPI_IO_SWAP_DISABLE;
  if (HAL_SPI_Init(&hspi6) != HAL_OK)
  {
    Error_Handler();
  }

}

static void MX_TIM6_Init(void)
{

  TIM_MasterConfigTypeDef sMasterConfig = {0};

  htim6.Instance = TIM6;
  htim6.Init.Prescaler = 0;
  htim6.Init.CounterMode = TIM_COUNTERMODE_UP;
  htim6.Init.Period = 65535;
  htim6.Init.AutoReloadPreload = TIM_AUTORELOAD_PRELOAD_DISABLE;
  if (HAL_TIM_Base_Init(&htim6) != HAL_OK)
  {
    Error_Handler();
  }
  sMasterConfig.MasterOutputTrigger = TIM_TRGO_RESET;
  sMasterConfig.MasterSlaveMode = TIM_MASTERSLAVEMODE_DISABLE;
  if (HAL_TIMEx_MasterConfigSynchronization(&htim6, &sMasterConfig) != HAL_OK)
  {
    Error_Handler();
  }

}

static void MX_TIM7_Init(void)
{

  TIM_MasterConfigTypeDef sMasterConfig = {0};

  htim7.Instance = TIM7;
  htim7.Init.Prescaler = 0;
  htim7.Init.CounterMode = TIM_COUNTERMODE_UP;
  htim7.Init.Period = 65535;
  htim7.Init.AutoReloadPreload = TIM_AUTORELOAD_PRELOAD_DISABLE;
  if (HAL_TIM_Base_Init(&htim7) != HAL_OK)
  {
    Error_Handler();
  }
  sMasterConfig.MasterOutputTrigger = TIM_TRGO_RESET;
  sMasterConfig.MasterSlaveMode = TIM_MASTERSLAVEMODE_DISABLE;
  if (HAL_TIMEx_MasterConfigSynchronization(&htim7, &sMasterConfig) != HAL_OK)
  {
    Error_Handler();
  }

}

static void MX_UART4_Init(void)
{

  huart4.Instance = UART4;
  huart4.Init.BaudRate = 115200;
  huart4.Init.WordLength = UART_WORDLENGTH_8B;
  huart4.Init.StopBits = UART_STOPBITS_1;
  huart4.Init.Parity = UART_PARITY_NONE;
  huart4.Init.Mode = UART_MODE_TX_RX;
  huart4.Init.HwFlowCtl = UART_HWCONTROL_NONE;
  huart4.Init.OverSampling = UART_OVERSAMPLING_16;
  huart4.Init.OneBitSampling = UART_ONE_BIT_SAMPLE_DISABLE;
  huart4.Init.ClockPrescaler = UART_PRESCALER_DIV1;
  huart4.AdvancedInit.AdvFeatureInit = UART_ADVFEATURE_NO_INIT;
  if (HAL_UART_Init(&huart4) != HAL_OK)
  {
    Error_Handler();
  }
  if (HAL_UARTEx_SetTxFifoThreshold(&huart4, UART_TXFIFO_THRESHOLD_1_8) != HAL_OK)
  {
    Error_Handler();
  }
  if (HAL_UARTEx_SetRxFifoThreshold(&huart4, UART_RXFIFO_THRESHOLD_1_8) != HAL_OK)
  {
    Error_Handler();
  }
  if (HAL_UARTEx_DisableFifoMode(&huart4) != HAL_OK)
  {
    Error_Handler();
  }

}

static void MX_UART5_Init(void)
{

  huart5.Instance = UART5;
  huart5.Init.BaudRate = 115200;
  huart5.Init.WordLength = UART_WORDLENGTH_8B;
  huart5.Init.StopBits = UART_STOPBITS_1;
  huart5.Init.Parity = UART_PARITY_NONE;
  huart5.Init.Mode = UART_MODE_TX_RX;
  huart5.Init.HwFlowCtl = UART_HWCONTROL_NONE;
  huart5.Init.OverSampling = UART_OVERSAMPLING_16;
  huart5.Init.OneBitSampling = UART_ONE_BIT_SAMPLE_DISABLE;
  huart5.Init.ClockPrescaler = UART_PRESCALER_DIV1;
  huart5.AdvancedInit.AdvFeatureInit = UART_ADVFEATURE_NO_INIT;
  if (HAL_UART_Init(&huart5) != HAL_OK)
  {
    Error_Handler();
  }
  if (HAL_UARTEx_SetTxFifoThreshold(&huart5, UART_TXFIFO_THRESHOLD_1_8) != HAL_OK)
  {
    Error_Handler();
  }
  if (HAL_UARTEx_SetRxFifoThreshold(&huart5, UART_RXFIFO_THRESHOLD_1_8) != HAL_OK)
  {
    Error_Handler();
  }
  if (HAL_UARTEx_DisableFifoMode(&huart5) != HAL_OK)
  {
    Error_Handler();
  }

}

static void MX_UART7_Init(void)
{

  huart7.Instance = UART7;
  huart7.Init.BaudRate = 115200;
  huart7.Init.WordLength = UART_WORDLENGTH_8B;
  huart7.Init.StopBits = UART_STOPBITS_1;
  huart7.Init.Parity = UART_PARITY_NONE;
  huart7.Init.Mode = UART_MODE_TX_RX;
  huart7.Init.HwFlowCtl = UART_HWCONTROL_NONE;
  huart7.Init.OverSampling = UART_OVERSAMPLING_16;
  huart7.Init.OneBitSampling = UART_ONE_BIT_SAMPLE_DISABLE;
  huart7.Init.ClockPrescaler = UART_PRESCALER_DIV1;
  huart7.AdvancedInit.AdvFeatureInit = UART_ADVFEATURE_NO_INIT;
  if (HAL_UART_Init(&huart7) != HAL_OK)
  {
    Error_Handler();
  }
  if (HAL_UARTEx_SetTxFifoThreshold(&huart7, UART_TXFIFO_THRESHOLD_1_8) != HAL_OK)
  {
    Error_Handler();
  }
  if (HAL_UARTEx_SetRxFifoThreshold(&huart7, UART_RXFIFO_THRESHOLD_1_8) != HAL_OK)
  {
    Error_Handler();
  }
  if (HAL_UARTEx_DisableFifoMode(&huart7) != HAL_OK)
  {
    Error_Handler();
  }

}

static void MX_USART1_UART_Init(void)
{

  huart1.Instance = USART1;
  huart1.Init.BaudRate = 115200;
  huart1.Init.WordLength = UART_WORDLENGTH_8B;
  huart1.Init.StopBits = UART_STOPBITS_1;
  huart1.Init.Parity = UART_PARITY_NONE;
  huart1.Init.Mode = UART_MODE_TX_RX;
  huart1.Init.HwFlowCtl = UART_HWCONTROL_NONE;
  huart1.Init.OverSampling = UART_OVERSAMPLING_16;
  huart1.Init.OneBitSampling = UART_ONE_BIT_SAMPLE_DISABLE;
  huart1.Init.ClockPrescaler = UART_PRESCALER_DIV1;
  huart1.AdvancedInit.AdvFeatureInit = UART_ADVFEATURE_NO_INIT;
  if (HAL_UART_Init(&huart1) != HAL_OK)
  {
    Error_Handler();
  }
  if (HAL_UARTEx_SetTxFifoThreshold(&huart1, UART_TXFIFO_THRESHOLD_1_8) != HAL_OK)
  {
    Error_Handler();
  }
  if (HAL_UARTEx_SetRxFifoThreshold(&huart1, UART_RXFIFO_THRESHOLD_1_8) != HAL_OK)
  {
    Error_Handler();
  }
  if (HAL_UARTEx_DisableFifoMode(&huart1) != HAL_OK)
  {
    Error_Handler();
  }

}

static void MX_USART2_UART_Init(void)
{

  huart2.Instance = USART2;
  huart2.Init.BaudRate = 115200;
  huart2.Init.WordLength = UART_WORDLENGTH_8B;
  huart2.Init.StopBits = UART_STOPBITS_1;
  huart2.Init.Parity = UART_PARITY_NONE;
  huart2.Init.Mode = UART_MODE_TX_RX;
  huart2.Init.HwFlowCtl = UART_HWCONTROL_NONE;
  huart2.Init.OverSampling = UART_OVERSAMPLING_16;
  huart2.Init.OneBitSampling = UART_ONE_BIT_SAMPLE_DISABLE;
  huart2.Init.ClockPrescaler = UART_PRESCALER_DIV1;
  huart2.AdvancedInit.AdvFeatureInit = UART_ADVFEATURE_NO_INIT;
  if (HAL_UART_Init(&huart2) != HAL_OK)
  {
    Error_Handler();
  }
  if (HAL_UARTEx_SetTxFifoThreshold(&huart2, UART_TXFIFO_THRESHOLD_1_8) != HAL_OK)
  {
    Error_Handler();
  }
  if (HAL_UARTEx_SetRxFifoThreshold(&huart2, UART_RXFIFO_THRESHOLD_1_8) != HAL_OK)
  {
    Error_Handler();
  }
  if (HAL_UARTEx_DisableFifoMode(&huart2) != HAL_OK)
  {
    Error_Handler();
  }

}

static void MX_USART6_UART_Init(void)
{

  huart6.Instance = USART6;
  huart6.Init.BaudRate = 115200;
  huart6.Init.WordLength = UART_WORDLENGTH_8B;
  huart6.Init.StopBits = UART_STOPBITS_1;
  huart6.Init.Parity = UART_PARITY_NONE;
  huart6.Init.Mode = UART_MODE_TX_RX;
  huart6.Init.HwFlowCtl = UART_HWCONTROL_NONE;
  huart6.Init.OverSampling = UART_OVERSAMPLING_16;
  huart6.Init.OneBitSampling = UART_ONE_BIT_SAMPLE_DISABLE;
  huart6.Init.ClockPrescaler = UART_PRESCALER_DIV1;
  huart6.AdvancedInit.AdvFeatureInit = UART_ADVFEATURE_NO_INIT;
  if (HAL_UART_Init(&huart6) != HAL_OK)
  {
    Error_Handler();
  }
  if (HAL_UARTEx_SetTxFifoThreshold(&huart6, UART_TXFIFO_THRESHOLD_1_8) != HAL_OK)
  {
    Error_Handler();
  }
  if (HAL_UARTEx_SetRxFifoThreshold(&huart6, UART_RXFIFO_THRESHOLD_1_8) != HAL_OK)
  {
    Error_Handler();
  }
  if (HAL_UARTEx_DisableFifoMode(&huart6) != HAL_OK)
  {
    Error_Handler();
  }

}

/* FMC initialization function */
static void MX_FMC_Init(void)
{

  FMC_SDRAM_TimingTypeDef SdramTiming = {0};

  /** Perform the SDRAM1 memory initialization sequence
  */
  hsdram1.Instance = FMC_SDRAM_DEVICE;
  /* hsdram1.Init */
  hsdram1.Init.SDBank = FMC_SDRAM_BANK1;
  hsdram1.Init.ColumnBitsNumber = FMC_SDRAM_COLUMN_BITS_NUM_9;
  hsdram1.Init.RowBitsNumber = FMC_SDRAM_ROW_BITS_NUM_13;
  hsdram1.Init.MemoryDataWidth = FMC_SDRAM_MEM_BUS_WIDTH_16;
  hsdram1.Init.InternalBankNumber = FMC_SDRAM_INTERN_BANKS_NUM_4;
  hsdram1.Init.CASLatency = FMC_SDRAM_CAS_LATENCY_2;
  hsdram1.Init.WriteProtection = FMC_SDRAM_WRITE_PROTECTION_DISABLE;
  hsdram1.Init.SDClockPeriod = FMC_SDRAM_CLOCK_PERIOD_3;
  hsdram1.Init.ReadBurst = FMC_SDRAM_RBURST_ENABLE;
  hsdram1.Init.ReadPipeDelay = FMC_SDRAM_RPIPE_DELAY_2;
  /* SdramTiming */
  SdramTiming.LoadToActiveDelay = 2;
  SdramTiming.ExitSelfRefreshDelay = 10;
  SdramTiming.SelfRefreshTime = 6;
  SdramTiming.RowCycleDelay = 9;
  SdramTiming.WriteRecoveryTime = 3;
  SdramTiming.RPDelay = 3;
  SdramTiming.RCDDelay = 3;

  if (HAL_SDRAM_Init(&hsdram1, &SdramTiming) != HAL_OK)
  {
    Error_Handler( );
  }

}

static void MX_GPIO_Init(void)
{
  GPIO_InitTypeDef GPIO_InitStruct = {0};

  /* GPIO Ports Clock Enable */
  __HAL_RCC_GPIOE_CLK_ENABLE();
  __HAL_RCC_GPIOC_CLK_ENABLE();
  __HAL_RCC_GPIOF_CLK_ENABLE();
  __HAL_RCC_GPIOH_CLK_ENABLE();
  __HAL_RCC_GPIOA_CLK_ENABLE();
  __HAL_RCC_GPIOB_CLK_ENABLE();
  __HAL_RCC_GPIOG_CLK_ENABLE();
  __HAL_RCC_GPIOD_CLK_ENABLE();

  /*Configure GPIO pin Output Level */
  HAL_GPIO_WritePin(GPIOF, GPIO_PIN_9, GPIO_PIN_RESET);

  /*Configure GPIO pin : PE3 */
  GPIO_InitStruct.Pin = GPIO_PIN_3;
  GPIO_InitStruct.Mode = GPIO_MODE_ANALOG;
  GPIO_InitStruct.Pull = GPIO_NOPULL;
  HAL_GPIO_Init(GPIOE, &GPIO_InitStruct);

  /*Configure GPIO pins : PC13 PC2 PC3 */
  GPIO_InitStruct.Pin = GPIO_PIN_13|GPIO_PIN_2|GPIO_PIN_3;
  GPIO_InitStruct.Mode = GPIO_MODE_ANALOG;
  GPIO_InitStruct.Pull = GPIO_NOPULL;
  HAL_GPIO_Init(GPIOC, &GPIO_InitStruct);

  /*Configure GPIO pin : PF9 */
  GPIO_InitStruct.Pin = GPIO_PIN_9;
  GPIO_InitStruct.Mode = GPIO_MODE_OUTPUT_PP;
  GPIO_InitStruct.Pull = GPIO_NOPULL;
  GPIO_InitStruct.Speed = GPIO_SPEED_FREQ_LOW;
  HAL_GPIO_Init(GPIOF, &GPIO_InitStruct);

  /*Configure GPIO pin : PF10 */
  GPIO_InitStruct.Pin = GPIO_PIN_10;
  GPIO_InitStruct.Mode = GPIO_MODE_ANALOG;
  GPIO_InitStruct.Pull = GPIO_NOPULL;
  HAL_GPIO_Init(GPIOF, &GPIO_InitStruct);

  /*Configure GPIO pins : PC0 PC1 */
  GPIO_InitStruct.Pin = GPIO_PIN_0|GPIO_PIN_1;
  GPIO_InitStruct.Mode = GPIO_MODE_INPUT;
  GPIO_InitStruct.Pull = GPIO_NOPULL;
  HAL_GPIO_Init(GPIOC, &GPIO_InitStruct);

  /*Configure GPIO pins : PA6 PA8 */
  GPIO_InitStruct.Pin = GPIO_PIN_6|GPIO_PIN_8;
  GPIO_InitStruct.Mode = GPIO_MODE_ANALOG;
  GPIO_InitStruct.Pull = GPIO_NOPULL;
  HAL_GPIO_Init(GPIOA, &GPIO_InitStruct);

  /*Configure GPIO pins : PB0 PB7 */
  GPIO_InitStruct.Pin = GPIO_PIN_0|GPIO_PIN_7;
  GPIO_InitStruct.Mode = GPIO_MODE_ANALOG;
  GPIO_InitStruct.Pull = GPIO_NOPULL;
  HAL_GPIO_Init(GPIOB, &GPIO_InitStruct);

  /*Configure GPIO pin : PB2 */
  GPIO_InitStruct.Pin = GPIO_PIN_2;
  GPIO_InitStruct.Mode = GPIO_MODE_INPUT;
  GPIO_InitStruct.Pull = GPIO_PULLUP;
  HAL_GPIO_Init(GPIOB, &GPIO_InitStruct);

  /*Configure GPIO pins : PD11 PD3 PD4 PD5 */
  GPIO_InitStruct.Pin = GPIO_PIN_11|GPIO_PIN_3|GPIO_PIN_4|GPIO_PIN_5;
  GPIO_InitStruct.Mode = GPIO_MODE_ANALOG;
  GPIO_InitStruct.Pull = GPIO_NOPULL;
  HAL_GPIO_Init(GPIOD, &GPIO_InitStruct);

  /*Configure GPIO pins : PG3 PG6 PG7 PG10
                           PG11 */
  GPIO_InitStruct.Pin = GPIO_PIN_3|GPIO_PIN_6|GPIO_PIN_7|GPIO_PIN_10
                          |GPIO_PIN_11;
  GPIO_InitStruct.Mode = GPIO_MODE_ANALOG;
  GPIO_InitStruct.Pull = GPIO_NOPULL;
  HAL_GPIO_Init(GPIOG, &GPIO_InitStruct);

  /*Configure GPIO pin : PC7 */
  GPIO_InitStruct.Pin = GPIO_PIN_7;
  GPIO_InitStruct.Mode = GPIO_MODE_INPUT;
  GPIO_InitStruct.Pull = GPIO_PULLUP;
  HAL_GPIO_Init(GPIOC, &GPIO_InitStruct);

}

void StartDefaultTask(void *argument)
{
  /* init code for USB_DEVICE */
  MX_USB_DEVICE_Init();
  /* USER CODE BEGIN 5 */

  cdh_main();

  /* Infinite loop */
  for(;;)
  {
    osDelay(1);
  }
  /* USER CODE END 5 */
}

 /* MPU Configuration */

void MPU_Config(void)
{
  MPU_Region_InitTypeDef MPU_InitStruct = {0};

  /* Disables the MPU */
  HAL_MPU_Disable();

  /** Initializes and configures the Region and the memory to be protected
  */
  MPU_InitStruct.Enable = MPU_REGION_ENABLE;
  MPU_InitStruct.Number = MPU_REGION_NUMBER0;
  MPU_InitStruct.BaseAddress = 0x0;
  MPU_InitStruct.Size = MPU_REGION_SIZE_4GB;
  MPU_InitStruct.SubRegionDisable = 0x87;
  MPU_InitStruct.TypeExtField = MPU_TEX_LEVEL0;
  MPU_InitStruct.AccessPermission = MPU_REGION_NO_ACCESS;
  MPU_InitStruct.DisableExec = MPU_INSTRUCTION_ACCESS_DISABLE;
  MPU_InitStruct.IsShareable = MPU_ACCESS_SHAREABLE;
  MPU_InitStruct.IsCacheable = MPU_ACCESS_NOT_CACHEABLE;
  MPU_InitStruct.IsBufferable = MPU_ACCESS_NOT_BUFFERABLE;

  HAL_MPU_ConfigRegion(&MPU_InitStruct);

  /** Initializes and configures the Region and the memory to be protected
  */
  MPU_InitStruct.Number = MPU_REGION_NUMBER1;
  MPU_InitStruct.BaseAddress = 0x08000000;
  MPU_InitStruct.Size = MPU_REGION_SIZE_2MB;
  MPU_InitStruct.SubRegionDisable = 0x88;
  MPU_InitStruct.TypeExtField = MPU_TEX_LEVEL1;
  MPU_InitStruct.AccessPermission = MPU_REGION_PRIV_RO;
  MPU_InitStruct.DisableExec = MPU_INSTRUCTION_ACCESS_ENABLE;
  MPU_InitStruct.IsShareable = MPU_ACCESS_NOT_SHAREABLE;
  MPU_InitStruct.IsCacheable = MPU_ACCESS_CACHEABLE;

  HAL_MPU_ConfigRegion(&MPU_InitStruct);

  /** Initializes and configures the Region and the memory to be protected
  */
  MPU_InitStruct.Number = MPU_REGION_NUMBER2;
  MPU_InitStruct.BaseAddress = 0xC0000000;
  MPU_InitStruct.Size = MPU_REGION_SIZE_32MB;
  MPU_InitStruct.SubRegionDisable = 0x0;
  MPU_InitStruct.AccessPermission = MPU_REGION_FULL_ACCESS;
  MPU_InitStruct.DisableExec = MPU_INSTRUCTION_ACCESS_DISABLE;
  MPU_InitStruct.IsCacheable = MPU_ACCESS_NOT_CACHEABLE;

  HAL_MPU_ConfigRegion(&MPU_InitStruct);
  /* Enables the MPU */
  HAL_MPU_Enable(MPU_PRIVILEGED_DEFAULT);

}

void HAL_TIM_PeriodElapsedCallback(TIM_HandleTypeDef *htim)
{
  if (htim->Instance == TIM1)
  {
    HAL_IncTick();
  }
}

void Error_Handler(void)
{
  __disable_irq();
  while (1)
  {
  }
}
